3VERSION ""

NS_ :

BS_:

BU_: XXX

BO_ 1184 BRAKE_MODULE: 8 XXX
 SG_ BRAKE_PRESSED : 59|1@1+ (1,0) [0|1] "" XXX

BO_ 566 STEER_ANGLE_SENSOR: 8 XXX
 SG_ STEER_ANGLE : 0|16@1- (1,0) [-2048|2048] "degree" XXX
 SG_ STEER_RATE : 16|16@1+ (1,0) [-2048|2048] "" XXX

BO_ 776 ENGINE_RPM_ID: 8 XXX
 SG_ ENGINE_RPM : 8|16@1+ (1,0) [0|10000] "rpm" XXX

BO_ 528 GAS_PEDAL: 8 XXX
 SG_ GAS_PEDAL : 16|8@1+ (1,0) [0|255] "" XXX

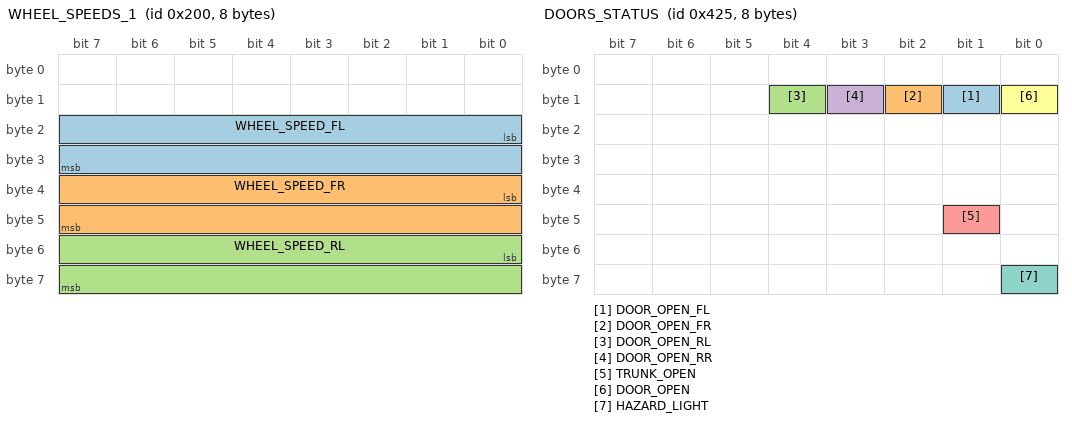
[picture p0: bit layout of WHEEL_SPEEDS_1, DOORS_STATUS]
BO_ 512 WHEEL_SPEEDS_1: 8 XXX
 SG_ WHEEL_SPEED_FL : 16|16@1+ (1,0) [0|25000] "kph" XXX
 SG_ WHEEL_SPEED_FR : 32|16@1+ (1,0) [0|25000] "kph" XXX
 SG_ WHEEL_SPEED_RL : 48|16@1+ (1,0) [0|25000] "kph" XXX

BO_ 520 WHEEL_SPEEDS_2: 8 XXX
 SG_ WHEEL_SPEED_RR : 32|16@1+ (1,0) [0|25000] "kph" XXX

BO_ 869 GEARBOX: 8 XXX
 SG_ GEAR_SHIFTER : 44|3@1+ (1,0) [0|7] "" XXX

BO_ 789 WARNING_SIGNALS: 8 XXX
 SG_ TURN_LEFT_SIGNAL : 33|1@1+ (1,0) [0|1] "" XXX
 SG_ TURN_RIGHT_SIGNAL : 34|1@1+ (1,0) [0|1] "" XXX

BO_ 753 STEER_MOMENT_SENSOR: 8 XXX
 SG_ STEER_MOMENT : 16|6@1+ (1,-21) [-15|15] "" XXX
 SG_ STEER_MOMENT_EPS : 0|8@1+ (1,0) [-100|100] "" XXX

BO_ 1061 DOORS_STATUS: 8 XXX
 SG_ DOOR_OPEN_FL : 9|1@1+ (1,0) [0|1] "" XXX
 SG_ DOOR_OPEN_FR : 10|1@1+ (1,0) [0|1] "" XXX
 SG_ DOOR_OPEN_RL : 12|1@1+ (1,0) [0|1] "" XXX
 SG_ DOOR_OPEN_RR : 11|1@1+ (1,0) [0|1] "" XXX
 SG_ TRUNK_OPEN : 41|1@1+ (1,0) [0|1] "" XXX
 SG_ DOOR_OPEN : 8|1@1+ (1,0) [0|1] "" XXX
 SG_ HAZARD_LIGHT : 56|1@1+ (1,0) [0|1] "" XXX

BO_ 839 SEATBELT_STATUS: 8 XXX
 SG_ SEATBELT_DRIVER_UNLATCHED : 0|1@0+ (1,0) [0|1] "" XXX

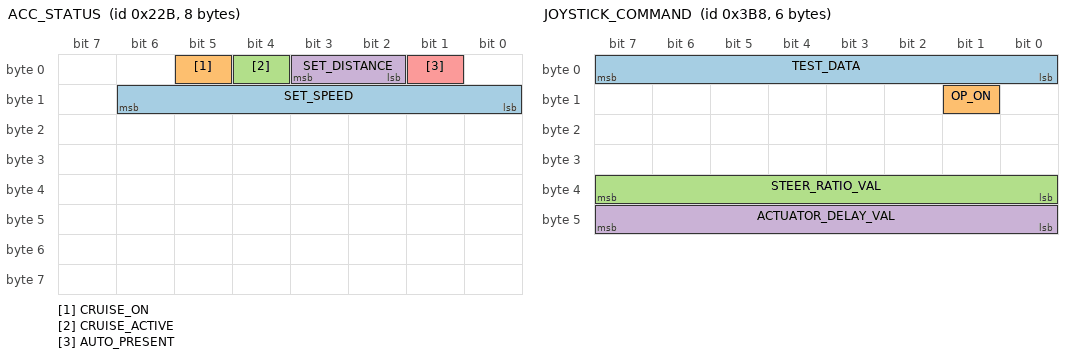
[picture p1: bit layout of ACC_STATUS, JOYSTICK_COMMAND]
BO_ 555 ACC_STATUS: 8 XXX
 SG_ SET_SPEED : 8|7@1+ (1,20) [0|200] "kph" XXX
 SG_ CRUISE_ON : 5|1@1+ (1,0) [0|1] "" XXX
 SG_ CRUISE_ACTIVE : 4|1@1+ (1,0) [0|1] "" XXX
 SG_ SET_DISTANCE : 2|2@1+ (1,0) [0|3] "" XXX
 SG_ AUTO_PRESENT : 1|1@1+ (1,0) [0|1] "" XXX

BO_ 782 BSW_STATUS: 8 XXX
 SG_ LEFT_WARNING : 2|1@1+ (1,0) [0|1] "" XXX
 SG_ RIGHT_WARNING : 3|1@1+ (1,0) [0|1] "" XXX

BO_ 912 ECO_BUT_ID: 8 XXX
 SG_ ECO_MODE : 40|1@1+ (1,0) [0|65535] "" XXX

BO_ 950 LKAS_COMMAND: 6 XXX
 SG_ CHECKSUM : 56|8@1+ (1,0) [0|255] "" XXX
 SG_ COUNTER : 48|4@1+ (1,0) [0|15] "" XXX
 SG_ LKAS_TEST_DATA_2 : 40|8@1+ (1,0) [0|255] "" XXX
 SG_ LKAS_ANGLE_OFFSET : 32|8@1+ (1,0) [0|255] "" XXX
 SG_ LKAS_LEAD_CAR : 14|1@1+ (1,0) [0|1] "" XXX
 SG_ LKAS_RIGHT_LINE : 13|1@1+ (1,0) [0|1] "" XXX
 SG_ LKAS_LEFT_LINE : 12|1@1+ (1,0) [0|1] "" XXX
 SG_ LKAS_ACTIVE : 11|1@1+ (1,0) [0|1] "" XXX
 SG_ LKAS_STEERING_ANGLE : 16|11@1- (1,-1024) [0|2048] "" XXX
 SG_ LKAS_STEERING_TORQUE : 0|11@1- (1,-1024) [0|2048] "" XXX

BO_ 952 JOYSTICK_COMMAND: 6 XXX
 SG_ TEST_DATA : 0|8@1+ (1,0) [0|255] "" XXX
 SG_ OP_ON : 9|1@1+ (1,0) [0|1] "" XXX
 SG_ STEER_RATIO_VAL : 32|8@1+ (1,0) [0|255] "" XXX
 SG_ ACTUATOR_DELAY_VAL : 40|8@1+ (1,0) [0|255] "" XXX

VAL_ 869 GEAR_SHIFTER 0 "P" 1 "R" 2 "N" 3 "D" 5 "L";
